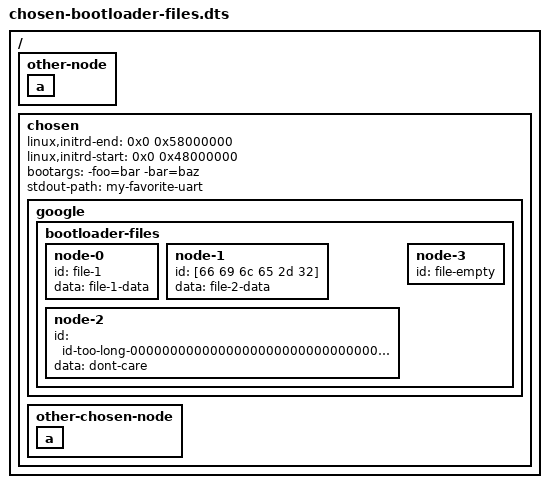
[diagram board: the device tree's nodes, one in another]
// Copyright 2025 The Fuchsia Authors. All rights reserved.
// Use of this source code is governed by a BSD-style license that can be
// found in the LICENSE file.
/dts-v1/;

/ {
	other-node {
		a {
		};
	};

	chosen {
		linux,initrd-end = <0x0 0x58000000>;
		linux,initrd-start = <0x0 0x48000000>;
		bootargs = "-foo=bar -bar=baz";
		stdout-path = "my-favorite-uart";

		google {
			bootloader-files {
				node-0 {
					id = "file-1";
					data = "file-1-data";
				};

				node-1 {
					id = [66 69 6c 65 2d 32];

					// "file-2"
					data = "file-2-data";
				};

				node-2 {
					id = "id-too-long-00000000000000000000000000000000000000000000000000000000000000000000000000000000000000000000000000000000000000000000000000000000000000000000000000000000000000000000000000000000000000000000000000000000000000000000000000000000000000000000000000000";
					data = "dont-care";
				};

				node-3 {
					id = "file-empty";
				};
			};
		};

		other-chosen-node {
			a {
			};
		};
	};
};
